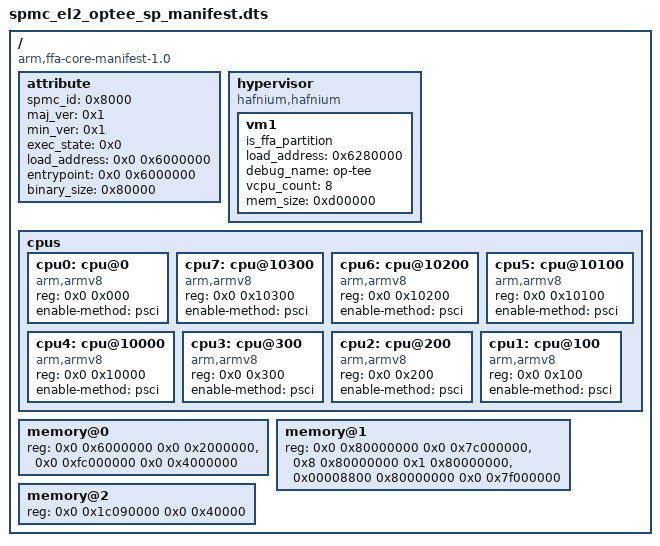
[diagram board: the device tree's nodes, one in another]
/*
 * Copyright 2022 The Hafnium Authors.
 *
 * Use of this source code is governed by a BSD-style
 * license that can be found in the LICENSE file or at
 * https://opensource.org/licenses/BSD-3-Clause.
 */

/dts-v1/;

/ {
	compatible = "arm,ffa-core-manifest-1.0";
	#address-cells = <2>;
	#size-cells = <2>;

	attribute {
		spmc_id = <0x8000>;
		maj_ver = <0x1>;
		min_ver = <0x1>;
		exec_state = <0x0>;
		load_address = <0x0 0x6000000>;
		entrypoint = <0x0 0x6000000>;
		binary_size = <0x80000>;
	};

	hypervisor {
		compatible = "hafnium,hafnium";
		vm1 {
			is_ffa_partition;
			load_address = <0x6280000>;
			debug_name = "op-tee";
			vcpu_count = <8>;
			mem_size = <0xd00000>;
		};
	};

	cpus {
		#address-cells = <2>;
		#size-cells = <0>;

		cpu0: cpu@0 {
			device_type = "cpu";
			compatible = "arm,armv8";
			reg = <0x0 0x000>;
			enable-method = "psci";
		};
		/*
		 * SPMC (Hafnium) requires secondary core nodes are declared
		 * in descending order.
		 */
		cpu7: cpu@10300 {
			device_type = "cpu";
			compatible = "arm,armv8";
			reg = <0x0 0x10300>;
			enable-method = "psci";
		};
		cpu6: cpu@10200 {
			device_type = "cpu";
			compatible = "arm,armv8";
			reg = <0x0 0x10200>;
			enable-method = "psci";
		};
		cpu5: cpu@10100 {
			device_type = "cpu";
			compatible = "arm,armv8";
			reg = <0x0 0x10100>;
			enable-method = "psci";
		};
		cpu4: cpu@10000 {
			device_type = "cpu";
			compatible = "arm,armv8";
			reg = <0x0 0x10000>;
			enable-method = "psci";
		};
		cpu3: cpu@300 {
			device_type = "cpu";
			compatible = "arm,armv8";
			reg = <0x0 0x300>;
			enable-method = "psci";
		};
		cpu2: cpu@200 {
			device_type = "cpu";
			compatible = "arm,armv8";
			reg = <0x0 0x200>;
			enable-method = "psci";
		};
		cpu1: cpu@100 {
			device_type = "cpu";
			compatible = "arm,armv8";
			reg = <0x0 0x100>;
			enable-method = "psci";
		};
	};

	/* Secure world memory */
	memory@0 {
		device_type = "memory";
		reg = <0x0 0x6000000 0x0 0x2000000>, /* Trusted DRAM */
		      <0x0 0xfc000000 0x0 0x4000000>; /* NS DRAM */
	};

	/* NS memory */
	memory@1 {
		device_type = "ns-memory";
		reg = <0x0 0x80000000 0x0 0x7c000000>,
		      <0x8 0x80000000 0x1 0x80000000>,
		      <0x00008800 0x80000000 0x0 0x7f000000>;

	};

	/* Device memory */
	memory@2 {
		device_type = "device-memory";
		reg = <0x0 0x1c090000 0x0 0x40000>; /* UART */
	};
};
